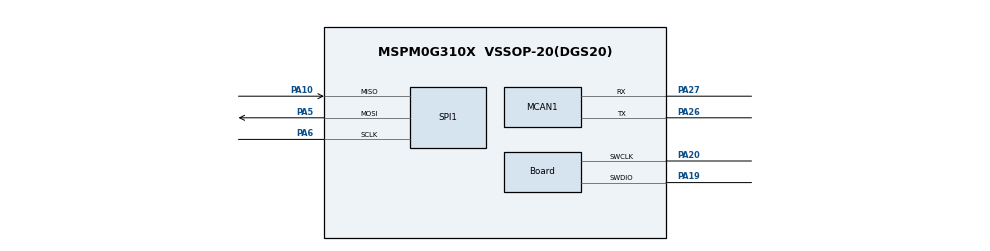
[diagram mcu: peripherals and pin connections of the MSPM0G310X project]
/**
 * @cliArgs --device "MSPM0G310X" --part "Default" --package "VSSOP-20(DGS20)" --product "mspm0_sdk@2.10.00.04"
 * @versions {"tool":"1.27.0+4565"}
 */

/**
 * Import the modules used in this configuration.
 */
const MCAN          = scripting.addModule("/ti/driverlib/MCAN", {}, false);
const MCAN1         = MCAN.addInstance();
const SPI           = scripting.addModule("/ti/driverlib/SPI", {}, false);
const SPI1          = SPI.addInstance();
const SYSCTL        = scripting.addModule("/ti/driverlib/SYSCTL");
const ProjectConfig = scripting.addModule("/ti/project_config/ProjectConfig");

/**
 * Write custom configuration values to the imported modules.
 */
const divider7       = system.clockTree["PLL_PDIV"];
divider7.divideValue = 2;

const multiplier2         = system.clockTree["PLL_QDIV"];
multiplier2.multiplyValue = 5;

const mux2       = system.clockTree["CANCLKMUX"];
mux2.inputSelect = "CANCLKMUX_PLLCLK1_OUT";

const mux3       = system.clockTree["EXCLKMUX"];
mux3.inputSelect = "EXCLKMUX_PLLCLK1_OUT";

MCAN1.$name                    = "MCAN0";
MCAN1.fdMode                   = false;
MCAN1.peripheral.$assign       = "CANFD0";
MCAN1.peripheral.rxPin.$assign = "PA27";
MCAN1.peripheral.txPin.$assign = "PA26";
MCAN1.txPinConfig.$name        = "ti_driverlib_gpio_GPIOPinGeneric4";
MCAN1.rxPinConfig.$name        = "ti_driverlib_gpio_GPIOPinGeneric5";

const Board                       = scripting.addModule("/ti/driverlib/Board", {}, false);
Board.peripheral.$assign          = "DEBUGSS";
Board.peripheral.swclkPin.$assign = "PA20";
Board.peripheral.swdioPin.$assign = "PA19";

SPI1.$name                              = "SPI";
SPI1.dataSize                           = 16;
SPI1.peripheral.$assign                 = "SPI0";
SPI1.peripheral.sclkPin.$assign         = "PA6";
SPI1.peripheral.mosiPin.$assign         = "PA5";
SPI1.peripheral.misoPin.$assign         = "PA10";
SPI1.sclkPinConfig.direction            = scripting.forceWrite("OUTPUT");
SPI1.sclkPinConfig.onlyInternalResistor = scripting.forceWrite(false);
SPI1.sclkPinConfig.passedPeripheralType = scripting.forceWrite("Digital");
SPI1.sclkPinConfig.$name                = "ti_driverlib_gpio_GPIOPinGeneric0";
SPI1.mosiPinConfig.direction            = scripting.forceWrite("OUTPUT");
SPI1.mosiPinConfig.hideOutputInversion  = scripting.forceWrite(false);
SPI1.mosiPinConfig.onlyInternalResistor = scripting.forceWrite(false);
SPI1.mosiPinConfig.passedPeripheralType = scripting.forceWrite("Digital");
SPI1.mosiPinConfig.$name                = "ti_driverlib_gpio_GPIOPinGeneric1";
SPI1.misoPinConfig.onlyInternalResistor = scripting.forceWrite(false);
SPI1.misoPinConfig.passedPeripheralType = scripting.forceWrite("Digital");
SPI1.misoPinConfig.$name                = "ti_driverlib_gpio_GPIOPinGeneric2";
SPI1.cs0PinConfig.direction             = scripting.forceWrite("OUTPUT");
SPI1.cs0PinConfig.hideOutputInversion   = scripting.forceWrite(false);
SPI1.cs0PinConfig.onlyInternalResistor  = scripting.forceWrite(false);
SPI1.cs0PinConfig.passedPeripheralType  = scripting.forceWrite("Digital");
SPI1.cs0PinConfig.$name                 = "ti_driverlib_gpio_GPIOPinGeneric3";

SYSCTL.CANCLKSource       = "SYSPLLCLK1";
SYSCTL.SYSPLL_CLK1En      = true;
SYSCTL.peripheral.$assign = "SYSCTL";

ProjectConfig.migrationCondition = true;

/**
 * Pinmux solution for unlocked pins/peripherals. This ensures that minor changes to the automatic solver in a future
 * version of the tool will not impact the pinmux you originally saw.  These lines can be completely deleted in order to
 * re-solve from scratch.
 */
SPI1.peripheral.cs0Pin.$suggestSolution = "PA2";
